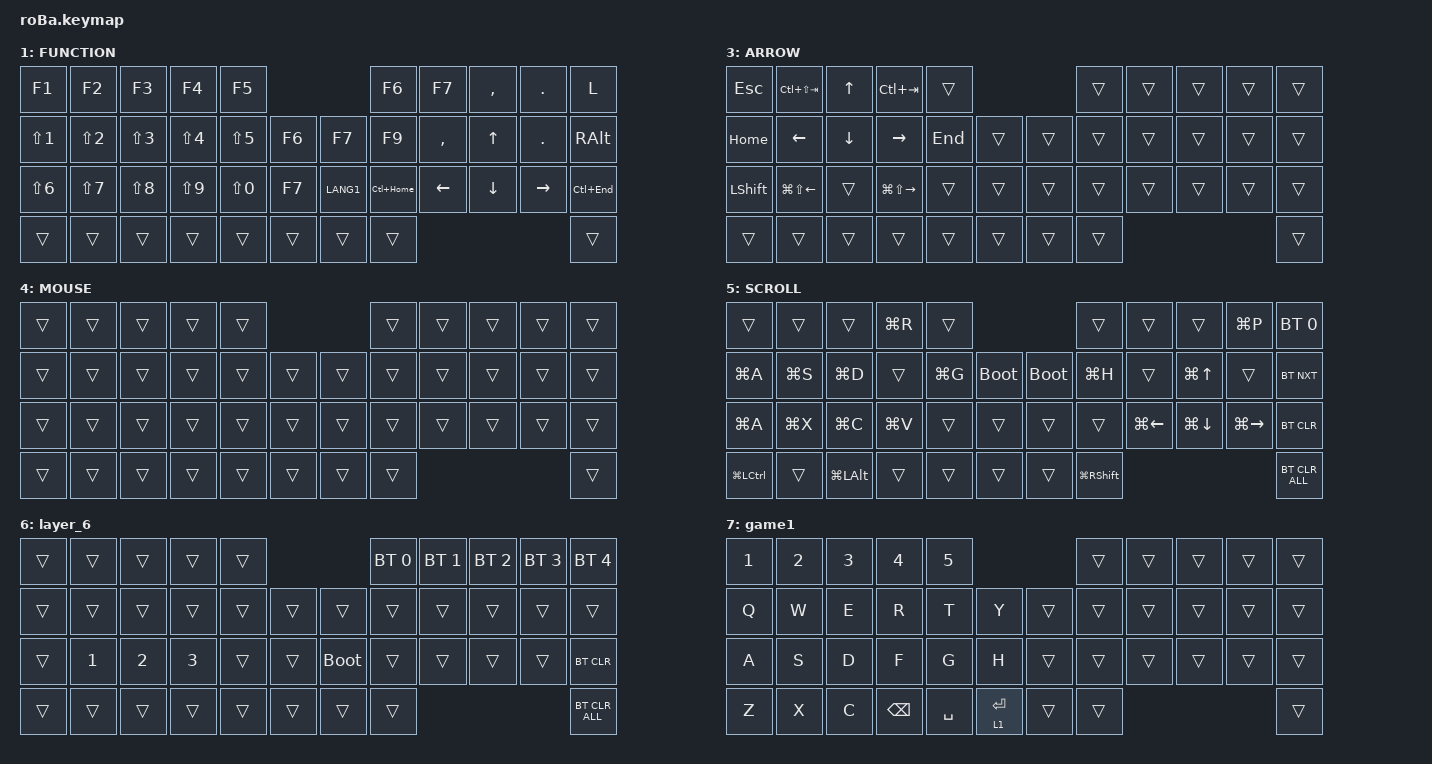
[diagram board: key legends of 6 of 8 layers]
#include <behaviors.dtsi>
#include <dt-bindings/zmk/bt.h>
#include <dt-bindings/zmk/keys.h>
#include <dt-bindings/zmk/pointing.h>

&mt {
    flavor = "balanced";
    quick-tap-ms = <0>;
};

&trackball {
    automouse-layer = <4>;
    scroll-layers = <5>;
};

/ {
    combos {
        compatible = "zmk,combos";

        tab {
            bindings = <&kp TAB>;
            key-positions = <11 12>;
        };

        esc {
            bindings = <&to_layer_0 ESC>;
            key-positions = <1 0>;
        };

        double_quotation {
            bindings = <&kp QUESTION>;
            key-positions = <20 21>;
        };

        eq {
            bindings = <&kp EQUAL>;
            key-positions = <26>;
        };

        scroll_combo {
            bindings = <&mo 5>;
            key-positions = <31 32>; // LCLK=31, RCLK=32 に修正済み
        };

        enter_combo {
            bindings = <&kp LANGUAGE_1>; // DOUBLE_QUOTES を RETURN に変更
            key-positions = <>; // キー位置はそのまま           
        };

        browser_back_combo {
            bindings = <&kp LA(LEFT_ARROW)>;
            key-positions = <18 19>;
        };

        susumu {
            bindings = <&kp LA(RIGHT_ARROW)>;
            key-positions = <19 20>;
        };

        undo_motonimodosu {
            bindings = <&kp LC(LS(Z))>;
            key-positions = <34 35>;
        };

        redo_yarinaoshi {
            bindings = <&kp LC(Z)>;
            key-positions = <23 22>;
        };

        layer0 {
            bindings = <&to 0>;
            key-positions = <40 39>;
        };

        screen_shot {
            bindings = <&kp LG(LS(S))>;
            key-positions = <0 9>;
        };

        combo_slash {
            bindings = <&kp SLASH>;
            key-positions = <4 14>;
        };

        combo_colon {
            bindings = <&kp COLON>;
            key-positions = <14 26>;
        };
    };

    macros {
        to_layer_0: to_layer_0 {
            compatible = "zmk,behavior-macro-one-param";
            #binding-cells = <1>;
            bindings = <&to 0 &macro_param_1to1 &kp MACRO_PLACEHOLDER>;
            label = "TO_LAYER_0";
        };
    };

    behaviors {
        lt_to_layer_0: lt_to_layer_0 {
            compatible = "zmk,behavior-hold-tap";
            label = "LAYER_TAP_TO_0";
            bindings = <&mo>, <&to_layer_0>;

            #binding-cells = <2>;
            tapping-term-ms = <200>;
        };
    };

    keymap {
        compatible = "zmk,keymap";

        default_layer {
            bindings = <
&kp Q             &kp W                  &kp E         &kp R          &kp T                                                 &kp Y        &kp U  &lt 5 I    &kp O            &kp P
&kp A             &kp S                  &kp D         &kp F          &kp G                                                 &kp H        &kp J  &kp K      &mt LCTRL MINUS  &kp L
&mt LEFT_SHIFT Z  &kp X                  &kp C         &kp V          &kp B                                                 &kp N        &kp M  &mkp LCLK  &mkp RCLK        &mt RIGHT_SHIFT SLASH
&kp LEFT_CONTROL  &lt_to_layer_0 5 LGUI  &kp LEFT_ALT  &mt LCTRL DEL  &kp SPACE  &lt_to_layer_0 3 ENTER      &kp BACKSPACE  &lt 1 ENTER                    &kp DEL          &kp DEL
            >;

            sensor-bindings = <&inc_dec_kp PG_UP PAGE_DOWN>;
        };

        FUNCTION {
            bindings = <
&kp F1            &kp F2            &kp F3            &kp F4            &kp F5                                   &kp F6        &kp F7          &kp COMMA       &kp DOT          &kp L
&kp LS(NUMBER_1)  &kp LS(NUMBER_2)  &kp LS(NUMBER_3)  &kp LS(NUMBER_4)  &kp LS(NUMBER_5)  &kp F6      &kp F7     &kp F9        &kp COMMA       &kp UP_ARROW    &kp PERIOD       &kp RALT
&kp LS(NUMBER_6)  &kp LS(NUMBER_7)  &kp LS(NUMBER_8)  &kp LS(NUMBER_9)  &kp LS(NUMBER_0)  &kp F7      &kp LANG1  &kp LC(HOME)  &kp LEFT_ARROW  &kp DOWN_ARROW  &kp RIGHT_ARROW  &kp LC(END)
&trans            &trans            &trans            &trans            &trans            &trans      &trans     &trans                                                         &trans
            >;
        };

        NUM {
            bindings = <
&kp NUMBER_1    &kp NUMBER_2    &kp NUMBER_3     &kp NUMBER_4  &kp NUMBER_5                                     &kp 1            &kp 2                 &kp 3                  &kp 4          &kp 5
&kp NUMBER_6    &kp NUMBER_7    &kp NUMBER_8     &kp NUMBER_9  &kp NUMBER_0  &kp SEMICOLON      &kp MINUS       &kp 6            &kp 7                 &kp 8                  &kp 9          &kp 0
&kp ESCAPE      &kp COMMA       &kp PERIOD       &kp MINUS     &kp EQUAL     &kp SLASH          &kp LEFT_BRACE  &kp RIGHT_BRACE  &kp LEFT_PARENTHESIS  &kp RIGHT_PARENTHESIS  &kp BACKSLASH  &kp BACKSLASH
&kp LEFT_SHIFT  &kp LEFT_BRACE  &kp RIGHT_BRACE  &kp TAB
            >;
        };

        ARROW {
            bindings = <
&kp ESCAPE      &kp LC(LS(TAB))         &kp UP_ARROW    &kp LC(TAB)              &trans                       &trans  &trans  &trans  &trans  &trans
&kp HOME        &kp LEFT_ARROW          &kp DOWN_ARROW  &kp RIGHT_ARROW          &kp END  &trans      &trans  &trans  &trans  &trans  &trans  &trans
&kp LEFT_SHIFT  &kp LG(LS(LEFT_ARROW))  &trans          &kp LG(LS(RIGHT_ARROW))  &trans   &trans      &trans  &trans  &trans  &trans  &trans  &trans
&trans          &trans                  &trans          &trans                   &trans   &trans      &trans  &trans                          &trans
            >;

            sensor-bindings = <&inc_dec_kp LC(PAGE_UP) LC(PAGE_DOWN)>;
        };

        MOUSE {
            bindings = <
&trans  &trans  &trans  &trans  &trans                      &trans  &trans  &trans  &trans  &trans
&trans  &trans  &trans  &trans  &trans  &trans      &trans  &trans  &trans  &trans  &trans  &trans
&trans  &trans  &trans  &trans  &trans  &trans      &trans  &trans  &trans  &trans  &trans  &trans
&trans  &trans  &trans  &trans  &trans  &trans      &trans  &trans                          &trans
            >;
        };

        SCROLL {
            bindings = <
&trans         &trans     &trans            &kp LG(R)  &trans                                   &trans               &trans        &trans              &kp LG(P)            &bt BT_SEL 0
&kp LG(A)      &kp LG(S)  &kp LG(D)         &trans     &kp LG(G)  &bootloader      &bootloader  &kp LG(H)            &trans        &kp LG(UP_ARROW)    &trans               &bt BT_NXT
&kp LG(A)      &kp LG(X)  &kp LG(C)         &kp LG(V)  &trans     &trans           &trans       &trans               &kp LG(LEFT)  &kp LG(DOWN_ARROW)  &kp LG(RIGHT_ARROW)  &bt BT_CLR
&kp LG(LCTRL)  &trans     &kp LG(LEFT_ALT)  &trans     &trans     &trans           &trans       &kp LG(RIGHT_SHIFT)                                                         &bt BT_CLR_ALL
            >;
        };

        layer_6 {
            bindings = <
&trans  &trans        &trans        &trans        &trans                           &bt BT_SEL 0  &bt BT_SEL 1  &bt BT_SEL 2  &bt BT_SEL 3  &bt BT_SEL 4
&trans  &trans        &trans        &trans        &trans  &trans      &trans       &trans        &trans        &trans        &trans        &trans
&trans  &kp NUMBER_1  &kp NUMBER_2  &kp NUMBER_3  &trans  &trans      &bootloader  &trans        &trans        &trans        &trans        &bt BT_CLR
&trans  &trans        &trans        &trans        &trans  &trans      &trans       &trans                                                  &bt BT_CLR_ALL
            >;
        };

        game1 {
            bindings = <
&kp NUMBER_1  &kp NUMBER_2  &kp NUMBER_3  &kp NUMBER_4   &kp N5                              &trans  &trans  &trans  &trans  &trans
&kp Q         &kp W         &kp E         &kp R          &kp T      &kp Y            &trans  &trans  &trans  &trans  &trans  &trans
&kp A         &kp S         &kp D         &kp F          &kp G      &kp H            &trans  &trans  &trans  &trans  &trans  &trans
&kp Z         &kp X         &kp C         &kp BACKSPACE  &kp SPACE  &lt 1 ENTER      &trans  &trans                          &trans
            >;
        };
    };
};

#define U_MOUSE_MOVE_MAX 6000  // 新しい最大速度設定（デフォルトは600）

#undef MOVE_UP
#undef MOVE_DOWN
#undef MOVE_LEFT
#undef MOVE_RIGHT

#define MOVE_UP MOVE_VERT(-U_MOUSE_MOVE_MAX)
#define MOVE_DOWN MOVE_VERT(U_MOUSE_MOVE_MAX)
#define MOVE_LEFT MOVE_HOR(-U_MOUSE_MOVE_MAX)
#define MOVE_RIGHT MOVE_HOR(U_MOUSE_MOVE_MAX)
